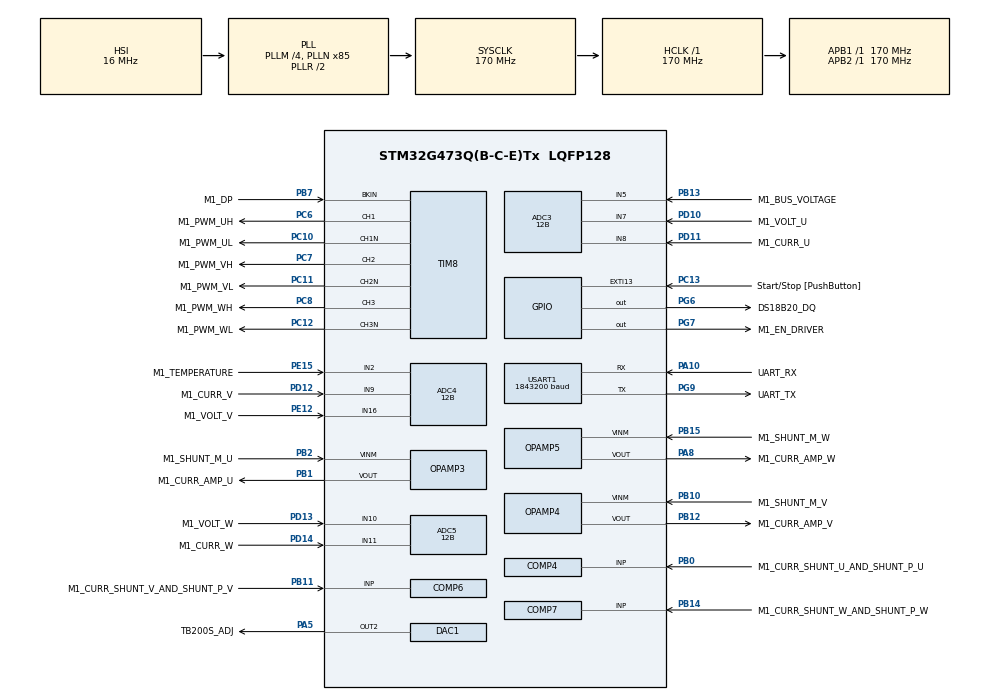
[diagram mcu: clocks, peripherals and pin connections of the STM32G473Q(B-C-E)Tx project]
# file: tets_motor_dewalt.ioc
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ADC3.Channel-1\#ChannelRegularConversion=ADC_CHANNEL_8
ADC3.Channel-2\#ChannelRegularConversion=ADC_CHANNEL_7
ADC3.Channel-3\#ChannelRegularConversion=ADC_CHANNEL_5
ADC3.ClockPrescaler=ADC_CLOCK_ASYNC_DIV1
ADC3.ContinuousConvMode=DISABLE
ADC3.DMAContinuousRequests=DISABLE
ADC3.DataAlign=ADC_DATAALIGN_LEFT
ADC3.DiscontinuousConvMode=DISABLE
ADC3.EOCSelection=ADC_EOC_SINGLE_CONV
ADC3.EnableAnalogWatchDog1=false
ADC3.EnableAnalogWatchDog2=false
ADC3.EnableAnalogWatchDog3=false
ADC3.EnableRegularConversion=ENABLE
ADC3.ExternalTrigConv=ADC_EXTERNALTRIG_T3_TRGO
ADC3.ExternalTrigConvEdge=ADC_EXTERNALTRIGCONVEDGE_FALLING
ADC3.LowPowerAutoWait=DISABLE
ADC3.NbrOfConversion=3
ADC3.NbrOfConversionFlag=1
ADC3.Offset-1\#ChannelRegularConversion=0
ADC3.Offset-2\#ChannelRegularConversion=0
ADC3.Offset-3\#ChannelRegularConversion=0
ADC3.OffsetNumber-1\#ChannelRegularConversion=ADC_OFFSET_NONE
ADC3.OffsetNumber-2\#ChannelRegularConversion=ADC_OFFSET_NONE
ADC3.OffsetNumber-3\#ChannelRegularConversion=ADC_OFFSET_NONE
ADC3.Overrun=ADC_OVR_DATA_PRESERVED
ADC3.Rank-1\#ChannelRegularConversion=1
ADC3.Rank-2\#ChannelRegularConversion=2
ADC3.Rank-3\#ChannelRegularConversion=3
ADC3.Resolution=ADC_RESOLUTION_12B
ADC3.SamplingTime-1\#ChannelRegularConversion=ADC_SAMPLETIME_6CYCLES_5
ADC3.SamplingTime-2\#ChannelRegularConversion=ADC_SAMPLETIME_6CYCLES_5
ADC3.SamplingTime-3\#ChannelRegularConversion=ADC_SAMPLETIME_6CYCLES_5
ADC3.ScanConvMode=ADC_SCAN_ENABLE
ADC3.master=1
ADC4.Channel-1\#ChannelRegularConversion=ADC_CHANNEL_9
ADC4.Channel-2\#ChannelRegularConversion=ADC_CHANNEL_16
ADC4.Channel-3\#ChannelRegularConversion=ADC_CHANNEL_2
ADC4.ClockPrescaler=ADC_CLOCK_ASYNC_DIV1
ADC4.ContinuousConvMode=DISABLE
ADC4.DMAContinuousRequests=DISABLE
ADC4.DataAlign=ADC_DATAALIGN_LEFT
ADC4.DiscontinuousConvMode=DISABLE
ADC4.EOCSelection=ADC_EOC_SINGLE_CONV
ADC4.EnableAnalogWatchDog1=false
ADC4.EnableAnalogWatchDog2=false
ADC4.EnableAnalogWatchDog3=false
ADC4.EnableRegularConversion=ENABLE
ADC4.ExternalTrigConv=ADC_EXTERNALTRIG_T3_TRGO
ADC4.ExternalTrigConvEdge=ADC_EXTERNALTRIGCONVEDGE_FALLING
ADC4.LowPowerAutoWait=DISABLE
ADC4.NbrOfConversion=3
ADC4.NbrOfConversionFlag=1
ADC4.Offset-1\#ChannelRegularConversion=0
ADC4.Offset-2\#ChannelRegularConversion=0
ADC4.Offset-3\#ChannelRegularConversion=0
ADC4.OffsetNumber-1\#ChannelRegularConversion=ADC_OFFSET_NONE
ADC4.OffsetNumber-2\#ChannelRegularConversion=ADC_OFFSET_NONE
ADC4.OffsetNumber-3\#ChannelRegularConversion=ADC_OFFSET_NONE
ADC4.Overrun=ADC_OVR_DATA_PRESERVED
ADC4.Rank-1\#ChannelRegularConversion=1
ADC4.Rank-2\#ChannelRegularConversion=2
ADC4.Rank-3\#ChannelRegularConversion=3
ADC4.Resolution=ADC_RESOLUTION_12B
ADC4.SamplingTime-1\#ChannelRegularConversion=ADC_SAMPLETIME_6CYCLES_5
ADC4.SamplingTime-2\#ChannelRegularConversion=ADC_SAMPLETIME_6CYCLES_5
ADC4.SamplingTime-3\#ChannelRegularConversion=ADC_SAMPLETIME_6CYCLES_5
ADC4.ScanConvMode=ADC_SCAN_ENABLE
ADC4.master=1
ADC5.Channel-1\#ChannelRegularConversion=ADC_CHANNEL_11
ADC5.Channel-2\#ChannelRegularConversion=ADC_CHANNEL_10
ADC5.Channel-3\#ChannelRegularConversion=ADC_CHANNEL_10
ADC5.ClockPrescaler=ADC_CLOCK_ASYNC_DIV1
ADC5.ContinuousConvMode=DISABLE
ADC5.DMAContinuousRequests=DISABLE
ADC5.DataAlign=ADC_DATAALIGN_LEFT
ADC5.DiscontinuousConvMode=DISABLE
ADC5.EOCSelection=ADC_EOC_SINGLE_CONV
ADC5.EnableAnalogWatchDog1=false
ADC5.EnableAnalogWatchDog2=false
ADC5.EnableAnalogWatchDog3=false
ADC5.EnableRegularConversion=ENABLE
ADC5.ExternalTrigConv=ADC_EXTERNALTRIG_T3_TRGO
ADC5.ExternalTrigConvEdge=ADC_EXTERNALTRIGCONVEDGE_FALLING
ADC5.LowPowerAutoWait=DISABLE
ADC5.NbrOfConversion=3
ADC5.NbrOfConversionFlag=1
ADC5.Offset-1\#ChannelRegularConversion=0
ADC5.Offset-2\#ChannelRegularConversion=0
ADC5.Offset-3\#ChannelRegularConversion=0
ADC5.OffsetNumber-1\#ChannelRegularConversion=ADC_OFFSET_NONE
ADC5.OffsetNumber-2\#ChannelRegularConversion=ADC_OFFSET_NONE
ADC5.OffsetNumber-3\#ChannelRegularConversion=ADC_OFFSET_NONE
ADC5.Overrun=ADC_OVR_DATA_PRESERVED
ADC5.Rank-1\#ChannelRegularConversion=1
ADC5.Rank-2\#ChannelRegularConversion=2
ADC5.Rank-3\#ChannelRegularConversion=3
ADC5.Resolution=ADC_RESOLUTION_12B
ADC5.SamplingTime-1\#ChannelRegularConversion=ADC_SAMPLETIME_6CYCLES_5
ADC5.SamplingTime-2\#ChannelRegularConversion=ADC_SAMPLETIME_6CYCLES_5
ADC5.SamplingTime-3\#ChannelRegularConversion=ADC_SAMPLETIME_6CYCLES_5
ADC5.ScanConvMode=ADC_SCAN_ENABLE
ADC5.master=1
DAC1.DAC_Channel-DAC_OUT2=DAC_CHANNEL_2
DAC1.DAC_ConnectOnChipPeripheral-DAC_OUT2=DAC_CHIPCONNECT_EXTERNAL
DAC1.DAC_OutputBuffer-DAC_OUT2=DAC_OUTPUTBUFFER_ENABLE
DAC3.DAC_Channel-DAC_OUT2_Int=DAC_CHANNEL_2
DAC4.DAC_Channel-DAC_OUT2_Int=DAC_CHANNEL_2
Dma.ADC3.2.Direction=DMA_PERIPH_TO_MEMORY
Dma.ADC3.2.EventEnable=DISABLE
Dma.ADC3.2.Instance=DMA2_Channel1
Dma.ADC3.2.MemDataAlignment=DMA_MDATAALIGN_HALFWORD
Dma.ADC3.2.MemInc=DMA_MINC_ENABLE
Dma.ADC3.2.Mode=DMA_CIRCULAR
Dma.ADC3.2.PeriphDataAlignment=DMA_PDATAALIGN_HALFWORD
Dma.ADC3.2.PeriphInc=DMA_PINC_DISABLE
Dma.ADC3.2.Polarity=HAL_DMAMUX_REQ_GEN_RISING
Dma.ADC3.2.Priority=DMA_PRIORITY_LOW
Dma.ADC3.2.RequestNumber=1
Dma.ADC3.2.SignalID=NONE
Dma.ADC3.2.SyncEnable=DISABLE
Dma.ADC3.2.SyncPolarity=HAL_DMAMUX_SYNC_NO_EVENT
Dma.ADC3.2.SyncRequestNumber=1
Dma.ADC3.2.SyncSignalID=NONE
Dma.ADC4.1.Direction=DMA_PERIPH_TO_MEMORY
Dma.ADC4.1.EventEnable=DISABLE
Dma.ADC4.1.Instance=DMA2_Channel2
Dma.ADC4.1.MemDataAlignment=DMA_MDATAALIGN_HALFWORD
Dma.ADC4.1.MemInc=DMA_MINC_ENABLE
Dma.ADC4.1.Mode=DMA_CIRCULAR
Dma.ADC4.1.PeriphDataAlignment=DMA_PDATAALIGN_HALFWORD
Dma.ADC4.1.PeriphInc=DMA_PINC_DISABLE
Dma.ADC4.1.Polarity=HAL_DMAMUX_REQ_GEN_RISING
Dma.ADC4.1.Priority=DMA_PRIORITY_LOW
Dma.ADC4.1.RequestNumber=1
Dma.ADC4.1.SignalID=NONE
Dma.ADC4.1.SyncEnable=DISABLE
Dma.ADC4.1.SyncPolarity=HAL_DMAMUX_SYNC_NO_EVENT
Dma.ADC4.1.SyncRequestNumber=1
Dma.ADC4.1.SyncSignalID=NONE
Dma.ADC5.0.Direction=DMA_PERIPH_TO_MEMORY
Dma.ADC5.0.EventEnable=DISABLE
Dma.ADC5.0.Instance=DMA2_Channel3
Dma.ADC5.0.MemDataAlignment=DMA_MDATAALIGN_HALFWORD
Dma.ADC5.0.MemInc=DMA_MINC_ENABLE
Dma.ADC5.0.Mode=DMA_CIRCULAR
Dma.ADC5.0.PeriphDataAlignment=DMA_PDATAALIGN_HALFWORD
Dma.ADC5.0.PeriphInc=DMA_PINC_DISABLE
Dma.ADC5.0.Polarity=HAL_DMAMUX_REQ_GEN_RISING
Dma.ADC5.0.Priority=DMA_PRIORITY_LOW
Dma.ADC5.0.RequestNumber=1
Dma.ADC5.0.SignalID=NONE
Dma.ADC5.0.SyncEnable=DISABLE
Dma.ADC5.0.SyncPolarity=HAL_DMAMUX_SYNC_NO_EVENT
Dma.ADC5.0.SyncRequestNumber=1
Dma.ADC5.0.SyncSignalID=NONE
Dma.Request0=ADC5
Dma.Request1=ADC4
Dma.Request2=ADC3
Dma.Request3=USART1_RX
Dma.Request4=USART1_TX
Dma.USART1_RX.3.Direction=DMA_PERIPH_TO_MEMORY
Dma.USART1_RX.3.EventEnable=DISABLE
Dma.USART1_RX.3.Instance=DMA1_Channel1
Dma.USART1_RX.3.MemDataAlignment=DMA_MDATAALIGN_BYTE
Dma.USART1_RX.3.MemInc=DMA_MINC_ENABLE
Dma.USART1_RX.3.Mode=DMA_NORMAL
Dma.USART1_RX.3.PeriphDataAlignment=DMA_PDATAALIGN_BYTE
Dma.USART1_RX.3.PeriphInc=DMA_PINC_DISABLE
Dma.USART1_RX.3.Polarity=HAL_DMAMUX_REQ_GEN_RISING
Dma.USART1_RX.3.Priority=DMA_PRIORITY_LOW
Dma.USART1_RX.3.RequestNumber=1
Dma.USART1_RX.3.SignalID=NONE
Dma.USART1_RX.3.SyncEnable=DISABLE
Dma.USART1_RX.3.SyncPolarity=HAL_DMAMUX_SYNC_NO_EVENT
Dma.USART1_RX.3.SyncRequestNumber=1
Dma.USART1_RX.3.SyncSignalID=NONE
Dma.USART1_TX.4.Direction=DMA_MEMORY_TO_PERIPH
Dma.USART1_TX.4.EventEnable=DISABLE
Dma.USART1_TX.4.Instance=DMA1_Channel2
Dma.USART1_TX.4.MemDataAlignment=DMA_MDATAALIGN_BYTE
Dma.USART1_TX.4.MemInc=DMA_MINC_ENABLE
Dma.USART1_TX.4.Mode=DMA_NORMAL
Dma.USART1_TX.4.PeriphDataAlignment=DMA_PDATAALIGN_BYTE
Dma.USART1_TX.4.PeriphInc=DMA_PINC_DISABLE
Dma.USART1_TX.4.Polarity=HAL_DMAMUX_REQ_GEN_RISING
Dma.USART1_TX.4.Priority=DMA_PRIORITY_LOW
Dma.USART1_TX.4.RequestNumber=1
Dma.USART1_TX.4.SignalID=NONE
Dma.USART1_TX.4.SyncEnable=DISABLE
Dma.USART1_TX.4.SyncPolarity=HAL_DMAMUX_SYNC_NO_EVENT
Dma.USART1_TX.4.SyncRequestNumber=1
Dma.USART1_TX.4.SyncSignalID=NONE
ExtraMW=MotorControl
ExtraMW.MotorControl.Config=MotorControl
ExtraMW.MotorControl.Mode=MotorControl
ExtraMW.MotorControl.Root=MCSDK_v6.4.2-Full/MotorControl
ExtraMW.MotorControl.Template=templates
Mcu.Family=STM32G4
Mcu.Name=STM32G473Q(B-C-E)Tx
Mcu.Package=LQFP128
MotorControl.ADC_CLOCK_WB_DIV=1
MotorControl.ADC_EXTRA_REG_CON_FAKE={'ADC3'\:[],'ADC4'\:[],'ADC5'\:[{'ip'\:'ADC5','channel'\:'ADC_Channel_10','pin'\:'PD13','isChShared'\:false,'sampling_time'\:6,'sampling_cycles'\:5,'label'\:'Fake','motor'\:1,'type'\:'Fake','rank'\:2}]}
MotorControl.ADC_MODE_REG_CON={'ADC3'\:true,'ADC4'\:true,'ADC5'\:true}
MotorControl.ADC_REFERENCE_VOLTAGE=3.3
MotorControl.ADC_REGULAR_REQS=[{'ip'\:'ADC3','channel'\:'ADC_Channel_8','pin'\:'PD11','isChShared'\:false,'sampling_time'\:6,'sampling_cycles'\:5,'label'\:'CURR_U','motor'\:1,'type'\:'CURR_U','rank'\:1},{'ip'\:'ADC3','channel'\:'ADC_Channel_7','pin'\:'PD10','isChShared'\:false,'sampling_time'\:6,'sampling_cycles'\:5,'label'\:'VOLT_U','motor'\:1,'type'\:'VOLT_U','rank'\:2},{'ip'\:'ADC3','channel'\:'ADC_Channel_5','pin'\:'PB13','isChShared'\:false,'sampling_time'\:6,'sampling_cycles'\:5,'label'\:'BUS_VOLTAGE','motor'\:1,'type'\:'BUS_VOLTAGE','rank'\:3},{'ip'\:'ADC4','channel'\:'ADC_Channel_9','pin'\:'PD12','isChShared'\:false,'sampling_time'\:6,'sampling_cycles'\:5,'label'\:'CURR_V','motor'\:1,'type'\:'CURR_V','rank'\:1},{'ip'\:'ADC4','channel'\:'ADC_Channel_16','pin'\:'PE12','isChShared'\:false,'sampling_time'\:6,'sampling_cycles'\:5,'label'\:'VOLT_V','motor'\:1,'type'\:'VOLT_V','rank'\:2},{'ip'\:'ADC4','channel'\:'ADC_Channel_2','pin'\:'PE15','isChShared'\:false,'sampling_time'\:6,'sampling_cycles'\:5,'label'\:'TEMPERATURE','motor'\:1,'type'\:'TEMPERATURE','rank'\:3},{'ip'\:'ADC5','channel'\:'ADC_Channel_11','pin'\:'PD14','isChShared'\:false,'sampling_time'\:6,'sampling_cycles'\:5,'label'\:'CURR_W','motor'\:1,'type'\:'CURR_W','rank'\:1},{'ip'\:'ADC5','channel'\:'ADC_Channel_10','pin'\:'PD13','isChShared'\:false,'sampling_time'\:6,'sampling_cycles'\:5,'label'\:'VOLT_W','motor'\:1,'type'\:'VOLT_W','rank'\:2}]
MotorControl.BOARD=B-G473E-ZEST1S
MotorControl.BUS_VOLTAGE_READING=true
MotorControl.CCMRAM_ENABLED=false
MotorControl.CLOCK_FREQUENCY=CPU_CLK_170_MHZ
MotorControl.CLOCK_SOURCE=INTERNAL
MotorControl.CPU_CLK_170_MHZ=true
MotorControl.CTLBOARD_NAME=B-G473E-ZEST1S
MotorControl.CUBE_MX_VER=6.17.0
MotorControl.CURRENT_READING_TOPOLOGY=THREE_SHUNT_INDEPENDENT_RESOURCES
MotorControl.CURR_SAMPLING_TIME=6
MotorControl.DBG_MCU_LOAD_MEASURE=false
MotorControl.DEBUG_DAC_FUNCTIONALITY_EN=false
MotorControl.DP_EMERGENCY_STOP_GPIO_PIN=LL_GPIO_PIN_7
MotorControl.DP_EMERGENCY_STOP_GPIO_PORT=GPIOB
MotorControl.DRIVES_NUMBER_SELECTION=SINGLEDRIVE
MotorControl.DRIVE_NUMBER=1
MotorControl.DRIVE_TYPE=FOC
MotorControl.ENCODER_AVAILABLE=false
MotorControl.ENCODER_PPR=400
MotorControl.EN_DRIVER_AVAILABLE=true
MotorControl.EN_DRIVER_GPIO_PIN=LL_GPIO_PIN_7
MotorControl.EN_DRIVER_GPIO_PORT=GPIOG
MotorControl.EN_DRIVER_POLARITY=ACTIVE_HIGH
MotorControl.EXT_CLOCK_FREQUENCY=INT_RC_OSC
MotorControl.FEEDBACK_NET_FILTERING=false
MotorControl.FLASH_SIZE=512
MotorControl.HALL_SENSORS_AVAILABLE=false
MotorControl.HIGH_SIDE_IDLE_STATE=false
MotorControl.HWV_CS=ThreeShunt_RawCurrents_Differential_ExternalGain_FilteredADCInput
MotorControl.HWV_DP=SingleErrorTrigger_FixedReference
MotorControl.HWV_OCP=ThreeShunt_RawCurrents_Protection_IntRef
MotorControl.HWV_PWM=DrivingHighAndLowSidesAndMasterEnable
MotorControl.HW_COMPLEMENTED_LOW_SIDE=false
MotorControl.HW_DEAD_TIME_NS=250
MotorControl.INT_RC_OSC=true
MotorControl.IPs=CORDIC,NVIC,RCC,SYS,MotorControl,TIM8,COMP4,DAC3,COMP6,DAC4,COMP7,OPAMP3,OPAMP4,OPAMP5,TIM3,ADC3,ADC4,ADC5,USART1,DMA
MotorControl.LOW_MEMORY_FOOTPRINT_REG=false
MotorControl.LOW_SIDE_IDLE_STATE=false
MotorControl.LOW_SIDE_SIGNALS_ENABLING=LS_PWM_TIMER
MotorControl.M1_AMPLIFICATION_GAIN=15
MotorControl.M1_ANGC={0,0,0,0,0,0,0,0}
MotorControl.M1_ANGLE_COMPENSATION_FACTOR=1.98
MotorControl.M1_AUXILIARY_SPEED_SENSOR=NONE
MotorControl.M1_BOARD_LIMIT_ACCEL_HIGH=10
MotorControl.M1_BOARD_LIMIT_ACCEL_LOW=7.5
MotorControl.M1_BOARD_LIMIT_REGEN_HIGH=19.44
MotorControl.M1_BOARD_LIMIT_REGEN_LOW=17.28
MotorControl.M1_BOARD_MAX_CURRENT=30
MotorControl.M1_BOARD_SOFT_OVERCURRENT_TRIP=30
MotorControl.M1_BUS_PROTECTION=false
MotorControl.M1_BUS_VOLTAGE_READING=true
MotorControl.M1_CONSTANT1_D=27069
MotorControl.M1_CONSTANT1_Q=27069
MotorControl.M1_CONSTANT2_QD=3745
MotorControl.M1_CS_ADC_NUM=3
MotorControl.M1_CS_ADC_PHASE_SHARED=NONE
MotorControl.M1_CS_ADC_RANK_U=1
MotorControl.M1_CS_ADC_RANK_V=1
MotorControl.M1_CS_ADC_RANK_W=1
MotorControl.M1_CS_ADC_U=ADC3
MotorControl.M1_CS_ADC_V=ADC4
MotorControl.M1_CS_ADC_W=ADC5
MotorControl.M1_CS_CHANNEL_U=8
MotorControl.M1_CS_CHANNEL_V=9
MotorControl.M1_CS_CHANNEL_W=11
MotorControl.M1_CS_OPAMP_DYNAMIC_OUTPUT_SWITCH=false
MotorControl.M1_CS_OPAMP_NUM=3
MotorControl.M1_CS_OPAMP_PHASE_SHARED=NONE
MotorControl.M1_CS_OPAMP_U=OPAMP3
MotorControl.M1_CS_OPAMP_V=OPAMP4
MotorControl.M1_CS_OPAMP_W=OPAMP5
MotorControl.M1_CURRENT_AMPLIFICATION_TOPO=INT_DIFFERENTIAL
MotorControl.M1_CURRENT_SCALE=440
MotorControl.M1_CURRENT_SENSING_TOPO=THREE_SHUNT
MotorControl.M1_CURR_SAMPLING_TIME=6
MotorControl.M1_DAC_CURRENT_THRESHOLD=4369
MotorControl.M1_DBG_OPEN_LOOP_ENABLE=false
MotorControl.M1_DC_CURRENT_RS_MEAS=5
MotorControl.M1_DEFAULT_CONTROL_MODE=STC_SPEED_MODE
MotorControl.M1_DEFAULT_FLUX_COMPONENT=0
MotorControl.M1_DEFAULT_TARGET_SPEED_RPM=1440
MotorControl.M1_DEFAULT_TORQUE_COMPONENT=0
MotorControl.M1_DISCONTINUOUS_PWM=false
MotorControl.M1_DP_BKIN_FILTER=4
MotorControl.M1_DP_BKIN_MODE=EXT_MODE
MotorControl.M1_DP_BKIN_POLARITY=EMSTOP_ACTIVE_LOW
MotorControl.M1_DP_DESTINATION=TIM_BKIN
MotorControl.M1_DP_TOPOLOGY=EXTERNAL
MotorControl.M1_DRIVE_TYPE=FOC
MotorControl.M1_ENCODER_PPR=400
MotorControl.M1_FREQUENCY_SCALE=267
MotorControl.M1_HALL_PHASE_SHIFT=300
MotorControl.M1_HALL_SENSORS_PLACEMENT=DEGREES_120
MotorControl.M1_HIGH_SIDE_IDLE_STATE=false
MotorControl.M1_HSO_ADC_SAMPLING_TIME=6.5
MotorControl.M1_HSO_DMACH_ADC_U=1
MotorControl.M1_HSO_DMACH_ADC_V=2
MotorControl.M1_HSO_DMACH_ADC_W=3
MotorControl.M1_HSO_DMA_ADC_U=DMA2
MotorControl.M1_HSO_DMA_ADC_V=DMA2
MotorControl.M1_HSO_DMA_ADC_W=DMA2
MotorControl.M1_HSO_EXTRA_TIM_SELEC=TIM3
MotorControl.M1_HSO_IRQ_HANDLER_DMA_ADC_U=DMA2_Channel1_IRQHandler
MotorControl.M1_HSO_IRQ_HANDLER_DMA_ADC_V=DMA2_Channel2_IRQHandler
MotorControl.M1_HSO_IRQ_HANDLER_DMA_ADC_W=DMA2_Channel3_IRQHandler
MotorControl.M1_HW_DEAD_TIME_NS=250
MotorControl.M1_ICL_ENABLED=false
MotorControl.M1_ID_DEMAG=-5
MotorControl.M1_INT_AMP_OPAMP3_PIN=[{'mode'\:'Standalone','name'\:'PB0','signal'\:'OPAMP3_VINP','label'\:'SHUNT_P_U'},{'mode'\:'Standalone','name'\:'PB2','signal'\:'OPAMP3_VINM','label'\:'SHUNT_M_U'},{'mode'\:'Standalone','name'\:'PB1','signal'\:'OPAMP3_VOUT','label'\:'CURR_AMP_U'}]
MotorControl.M1_INT_AMP_OPAMP4_PIN=[{'mode'\:'Standalone','name'\:'PB11','signal'\:'OPAMP4_VINP','label'\:'SHUNT_P_V'},{'mode'\:'Standalone','name'\:'PB10','signal'\:'OPAMP4_VINM','label'\:'SHUNT_M_V'},{'mode'\:'Standalone','name'\:'PB12','signal'\:'OPAMP4_VOUT','label'\:'CURR_AMP_V'}]
MotorControl.M1_INT_AMP_OPAMP5_PIN=[{'mode'\:'Standalone','name'\:'PB14','signal'\:'OPAMP5_VINP','label'\:'SHUNT_P_W'},{'mode'\:'Standalone','name'\:'PB15','signal'\:'OPAMP5_VINM','label'\:'SHUNT_M_W'},{'mode'\:'Standalone','name'\:'PA8','signal'\:'OPAMP5_VOUT','label'\:'CURR_AMP_W'}]
MotorControl.M1_INT_AMP_OPAMPS=['OPAMP3','OPAMP4','OPAMP5']
MotorControl.M1_IQMAX=28
MotorControl.M1_KSAMPLE_DELAY=0.2
MotorControl.M1_LDLQ_RATIO=1.000
MotorControl.M1_LOW_SIDE_IDLE_STATE=false
MotorControl.M1_LOW_SIDE_SIGNALS_ENABLING=LS_PWM_TIMER
MotorControl.M1_LS=0.000017
MotorControl.M1_MAX_APPLICATION_SPEED=4500
MotorControl.M1_MAX_MODULATION_INDEX=100
MotorControl.M1_MIN_APPLICATION_SPEED=0
MotorControl.M1_MOTOR_MAX_SPEED_RPM=4500
MotorControl.M1_MOTOR_NAME=DeWalt DCD996NT-TY2 Brus
MotorControl.M1_MOTOR_RATED_FLUX=0.013006791
MotorControl.M1_MOTOR_VOLTAGE_CONSTANT=0.5
MotorControl.M1_NOMINAL_BUS_VOLTAGE_V=18
MotorControl.M1_NOMINAL_CURRENT=30
MotorControl.M1_OCP_BKIN_FILTER=4
MotorControl.M1_OCP_BKIN_MODE=INT_MODE
MotorControl.M1_OCP_BKIN_POLARITY=EMSTOP_ACTIVE_HIGH
MotorControl.M1_OCP_COMP_SRC=DAC
MotorControl.M1_OCP_COMP_U=COMP4
MotorControl.M1_OCP_COMP_V=COMP6
MotorControl.M1_OCP_COMP_W=COMP7
MotorControl.M1_OCP_DAC_CHANNEL_U=OUT2
MotorControl.M1_OCP_DAC_CHANNEL_V=OUT2
MotorControl.M1_OCP_DAC_CHANNEL_W=OUT1
MotorControl.M1_OCP_DAC_U=DAC3
MotorControl.M1_OCP_DAC_V=DAC4
MotorControl.M1_OCP_DAC_W=DAC4
MotorControl.M1_OCP_DESTINATION=TIM_BKIN
MotorControl.M1_OCP_TOPOLOGY=EMBEDDED
MotorControl.M1_OFST={0,0,0,0,0,0,0,0}
MotorControl.M1_ON_OVER_VOLTAGE=TURN_OFF_PWM
MotorControl.M1_OVERMODULATION=false
MotorControl.M1_OVP_THRESHOLD_HIGH=21.6
MotorControl.M1_OV_TEMPERATURE_HYSTERESIS_C=10
MotorControl.M1_OV_TEMPERATURE_PROT_ENABLING=true
MotorControl.M1_OV_TEMPERATURE_THRESHOLD_C=120
MotorControl.M1_OV_VOLTAGE_PROT_ENABLING=true
MotorControl.M1_OV_VOLTAGE_THRESHOLD_V=21.6
MotorControl.M1_PHASE_VOLTAGE_PARTITIONING_FACTOR=0.063
MotorControl.M1_PID_FLUX_KD_DEFAULT=100
MotorControl.M1_PID_FLUX_KI_DEFAULT=751
MotorControl.M1_PID_FLUX_KP_DEFAULT=2553
MotorControl.M1_PID_SPD_KI=7.15693773016927
MotorControl.M1_PID_SPD_KP=0.29673580049046194
MotorControl.M1_PID_TORQUE_KD_DEFAULT=100
MotorControl.M1_PID_TORQUE_KI_DEFAULT=751
MotorControl.M1_PID_TORQUE_KP_DEFAULT=2553
MotorControl.M1_POLE_PAIR_NUM=2
MotorControl.M1_POLPULSES_ACTIVATTION_FLAG=true
MotorControl.M1_POLPULSES_NB_DECAY_PERIODS=2
MotorControl.M1_POLPULSES_NB_PULSE_PERIODS=2
MotorControl.M1_POLPULSES_PULSE_CURRENT_GOAL=14.0
MotorControl.M1_POTENTIOMETER_ENABLE=false
MotorControl.M1_POWERBOARD_NAME=STDES-LVHP01_48V
MotorControl.M1_PWM_CHARGE_BOOT_CAP_DUTY_CYCLES=0.000
MotorControl.M1_PWM_CHARGE_BOOT_CAP_MS=10
MotorControl.M1_PWM_DRIVER_PN=L6491
MotorControl.M1_PWM_FREQUENCY=16000
MotorControl.M1_PWM_TIMER_BRK_IRQ=TIM8_BRK
MotorControl.M1_PWM_TIMER_CC_IRQ=TIM8_CC
MotorControl.M1_PWM_TIMER_SELECTION=PWM_TIM8
MotorControl.M1_PWM_TIMER_UP_IRQ=TIM8_UP
MotorControl.M1_REGULATION_EXECUTION_RATE=1
MotorControl.M1_RS=0.01
MotorControl.M1_RSDC_ESTIMATION_FLAG=true
MotorControl.M1_RSHUNT=0.001
MotorControl.M1_SEGDIV=0
MotorControl.M1_SHARED_SIGNAL_ENABLE=false
MotorControl.M1_SPD_DIFFERENTIAL_TERM_ENABLING=false
MotorControl.M1_SPEED_LOOP_FREQUENCY_HZ=1000
MotorControl.M1_SPEED_SENSOR=HSO
MotorControl.M1_SS_MEAS_ERRORS_BEFORE_FAULTS=3
MotorControl.M1_SW_DEADTIME_NS=225
MotorControl.M1_T0_C=25
MotorControl.M1_TEMPERATURE_READING=true
MotorControl.M1_TEMP_ADC_RANK=3
MotorControl.M1_TEMP_ADC_SAMPLING_TIME=6
MotorControl.M1_TEMP_FDBK_ADC=ADC4
MotorControl.M1_TEMP_FDBK_CHANNEL=ADC_CHANNEL_2
MotorControl.M1_TNOISE_NS=500
MotorControl.M1_TRISE_NS=100
MotorControl.M1_T_MAX=120
MotorControl.M1_UD_VOLTAGE_THRESHOLD_V=5.0
MotorControl.M1_USE_INTERNAL_OPAMP=true
MotorControl.M1_UV_VOLTAGE_PROT_ENABLING=true
MotorControl.M1_V0_V=0.29
MotorControl.M1_VBUS_ADC=ADC3
MotorControl.M1_VBUS_ADC_RANK=3
MotorControl.M1_VBUS_ADC_SAMPLING_TIME=6
MotorControl.M1_VBUS_CHANNEL=ADC_CHANNEL_5
MotorControl.M1_VBUS_PARTITIONING_FACTOR=0.02900232018561485
MotorControl.M1_VOLTAGE_FILTER_POLE_RPS=3154
MotorControl.M1_VOLTAGE_SCALE=105
MotorControl.M1_VS_ADC_RANK_U=2
MotorControl.M1_VS_ADC_RANK_V=2
MotorControl.M1_VS_ADC_RANK_W=2
MotorControl.M1_VS_ADC_U=ADC3
MotorControl.M1_VS_ADC_V=ADC4
MotorControl.M1_VS_ADC_W=ADC5
MotorControl.M1_dV_dT=0.025
MotorControl.MAX_READABLE_CURRENT=110
MotorControl.MCPA_OVER_UART_A_STREAM=10
MotorControl.MCP_ASPEP_OVER_UART=true
MotorControl.MCP_ASYNC_EN=true
MotorControl.MCP_ASYNC_OVER_ASPEP_EN=true
MotorControl.MCP_ASYNC_OVER_UART_A_EN=true
MotorControl.MCP_DMACH_RX_UART_A=1
MotorControl.MCP_DMACH_TX_UART_A=2
MotorControl.MCP_DMA_RX_UART_A=DMA1
MotorControl.MCP_DMA_TX_UART_A=DMA1
MotorControl.MCP_EN=true
MotorControl.MCP_IRQ_HANDLER_DMA_RX_UART_A=DMA1_Channel1_IRQHandler
MotorControl.MCP_IRQ_HANDLER_UART_A=USART1_IRQHandler
MotorControl.MCP_OVER_ASPEP_EN=true
MotorControl.MCP_OVER_STLNK_EN=false
MotorControl.MCP_OVER_UART_A_EN=true
MotorControl.MCP_OVER_UART_B_EN=false
MotorControl.MCP_RX_SYNC_PAYLOAD_MAX=256
MotorControl.MCP_TX_ASYNC_PAYLOAD_MAX_UART_A=2048
MotorControl.MCP_TX_SYNC_PAYLOAD_MAX=256
MotorControl.MCU=STM32G473QE
MotorControl.MCU_FAMILY=STM32G4
MotorControl.MCU_LINE=STM32G4x3
MotorControl.MCU_NAME=STM32G473Q(B-C-E)Tx
MotorControl.MCU_PACKAGE=LQFP128
MotorControl.MCU_TYPE=STM32G473QE
MotorControl.MCU_USERNAME=STM32G473QETx
MotorControl.MC_WORKBENCH_VERSION=6.4.2
MotorControl.MOTOR_PROFILER=false
MotorControl.MOTOR_TYPE=PMSM
MotorControl.OCPA_DAC_INTERNAL_PIN=true
MotorControl.OCPA_INVERTINGINPUT=COMPX_InvertingInput_DAC3
MotorControl.OCPA_INVERTINGINPUT_DAC_OUT=OUT2
MotorControl.OCPA_INVERTINGINPUT_GPIO_PIN=LL_GPIO_PIN_4
MotorControl.OCPA_INVERTINGINPUT_GPIO_PORT=GPIOA
MotorControl.OCPA_INVERTINGINPUT_MODE=INT_MODE
MotorControl.OCPA_NONINVERTINGINPUT=COMP4_NonInvertingInput_PB0
MotorControl.OCPA_NONINVERTINGINPUT_GPIO_PIN=LL_GPIO_PIN_0
MotorControl.OCPA_NONINVERTINGINPUT_GPIO_PORT=GPIOB
MotorControl.OCPA_OUTPUT=COMP_Output_TIM1BKIN2
MotorControl.OCPA_OUTPUTPOL=COMP_OutputPol_NonInverted
MotorControl.OCPA_OUTPUT_GPIO_PIN=LL_GPIO_PIN_4
MotorControl.OCPA_OUTPUT_GPIO_PORT=GPIOA
MotorControl.OCPA_OUTPUT_MODE=INT_MODE
MotorControl.OCPA_SELECTION=COMP4
MotorControl.OCPB_DAC_INTERNAL_PIN=true
MotorControl.OCPB_INVERTINGINPUT=COMPX_InvertingInput_DAC4
MotorControl.OCPB_INVERTINGINPUT_DAC_OUT=OUT2
MotorControl.OCPB_INVERTINGINPUT_GPIO_PIN=LL_GPIO_PIN_4
MotorControl.OCPB_INVERTINGINPUT_GPIO_PORT=GPIOA
MotorControl.OCPB_INVERTINGINPUT_MODE=INT_MODE
MotorControl.OCPB_NONINVERTINGINPUT=COMP6_NonInvertingInput_PB11
MotorControl.OCPB_NONINVERTINGINPUT_GPIO_PIN=LL_GPIO_PIN_11
MotorControl.OCPB_NONINVERTINGINPUT_GPIO_PORT=GPIOB
MotorControl.OCPB_OUTPUT=COMP_Output_TIM1BKIN2
MotorControl.OCPB_OUTPUTPOL=COMP_OutputPol_NonInverted
MotorControl.OCPB_OUTPUT_GPIO_PIN=LL_GPIO_PIN_4
MotorControl.OCPB_OUTPUT_GPIO_PORT=GPIOA
MotorControl.OCPB_OUTPUT_MODE=INT_MODE
MotorControl.OCPB_SELECTION=COMP6
MotorControl.OCPC_DAC_INTERNAL_PIN=true
MotorControl.OCPC_INVERTINGINPUT=COMPX_InvertingInput_DAC4
MotorControl.OCPC_INVERTINGINPUT_DAC_OUT=OUT1
MotorControl.OCPC_INVERTINGINPUT_GPIO_PIN=LL_GPIO_PIN_4
MotorControl.OCPC_INVERTINGINPUT_GPIO_PORT=GPIOA
MotorControl.OCPC_INVERTINGINPUT_MODE=INT_MODE
MotorControl.OCPC_NONINVERTINGINPUT=COMP7_NonInvertingInput_PB14
MotorControl.OCPC_NONINVERTINGINPUT_GPIO_PIN=LL_GPIO_PIN_14
MotorControl.OCPC_NONINVERTINGINPUT_GPIO_PORT=GPIOB
MotorControl.OCPC_OUTPUT=COMP_Output_TIM1BKIN2
MotorControl.OCPC_OUTPUTPOL=COMP_OutputPol_NonInverted
MotorControl.OCPC_OUTPUT_GPIO_PIN=LL_GPIO_PIN_4
MotorControl.OCPC_OUTPUT_GPIO_PORT=GPIOA
MotorControl.OCPC_OUTPUT_MODE=INT_MODE
MotorControl.OCPC_SELECTION=COMP7
MotorControl.OCP_FILTER=COMP_Mode_HighSpeed
MotorControl.OCP_INVERTINGINPUT=COMPX_InvertingInput_V_REF
MotorControl.OCP_INVERTINGINPUT_MODE=INT_MODE
MotorControl.OCP_SELECTION=COMP1
MotorControl.ON_OVER_VOLTAGE=TURN_OFF_PWM
MotorControl.OPAMP_PGAGAIN=OPAMP_OPAMP_PGAGain_16
MotorControl.OPAMP_TYPE_GAIN=EXTERNAL
MotorControl.OV_TEMPERATURE_PROT_ENABLING=true
MotorControl.OV_VOLTAGE_PROT_ENABLING=true
MotorControl.PHASE_UH_GPIO_PIN=LL_GPIO_PIN_6
MotorControl.PHASE_UH_GPIO_PORT=GPIOC
MotorControl.PHASE_UH_POLARITY=H_ACTIVE_HIGH
MotorControl.PHASE_UL_GPIO_PIN=LL_GPIO_PIN_10
MotorControl.PHASE_UL_GPIO_PORT=GPIOC
MotorControl.PHASE_UL_POLARITY=L_ACTIVE_LOW
MotorControl.PHASE_U_PWM_CHANNEL=TIM_Channel_1
MotorControl.PHASE_VH_GPIO_PIN=LL_GPIO_PIN_7
MotorControl.PHASE_VH_GPIO_PORT=GPIOC
MotorControl.PHASE_VH_POLARITY=H_ACTIVE_HIGH
MotorControl.PHASE_VL_GPIO_PIN=LL_GPIO_PIN_11
MotorControl.PHASE_VL_GPIO_PORT=GPIOC
MotorControl.PHASE_VL_POLARITY=L_ACTIVE_LOW
MotorControl.PHASE_V_PWM_CHANNEL=TIM_Channel_2
MotorControl.PHASE_WH_GPIO_PIN=LL_GPIO_PIN_8
MotorControl.PHASE_WH_GPIO_PORT=GPIOC
MotorControl.PHASE_WH_POLARITY=H_ACTIVE_HIGH
MotorControl.PHASE_WL_GPIO_PIN=LL_GPIO_PIN_12
MotorControl.PHASE_WL_GPIO_PORT=GPIOC
MotorControl.PHASE_WL_POLARITY=L_ACTIVE_LOW
MotorControl.PHASE_W_PWM_CHANNEL=TIM_Channel_3
MotorControl.POTENTIOMETER_READING=false
MotorControl.PWM_FREQUENCY=16000
MotorControl.PWM_TIMER_SELECTION=PWM_TIM8
MotorControl.REGULATION_EXECUTION_RATE=1
MotorControl.RTOS=NONE
MotorControl.R_BRAKE_SWITCH_OFF_THRES_V=17
MotorControl.SENSORLESS_HIGHSPEEDOBSERVER=true
MotorControl.SINGLEDRIVE=true
MotorControl.SPD_DIFFERENTIAL_TERM_ENABLING=false
MotorControl.SPEED_SENSOR_SELECTION=SENSORLESS_HIGHSPEEDOBSERVER
MotorControl.START_STOP_BTN=true
MotorControl.START_STOP_GPIO_IRQ=EXTI15_10
MotorControl.START_STOP_GPIO_PIN=LL_GPIO_PIN_13
MotorControl.START_STOP_GPIO_PORT=GPIOC
MotorControl.START_STOP_POLARITY=DIN_ACTIVE_LOW
MotorControl.START_STOP_POLARITY_EDGE=GPIO_PULLUP
MotorControl.STM32G473QE=true
MotorControl.SW_DEADTIME_NS=225
MotorControl.TEMPERATURE_READING=true
MotorControl.TEMP_ADC_SAMPLING_TIME=6
MotorControl.TEMP_FDBK_ADC=ADC4
MotorControl.TEMP_FDBK_CHANNEL=ADC_CHANNEL_2
MotorControl.TEMP_FDBK_GPIO_PIN=LL_GPIO_PIN_15
MotorControl.TEMP_FDBK_GPIO_PORT=GPIOE
MotorControl.TFDIFFERENTIAL_TERM_ENABLING=false
MotorControl.THREE_SHUNT_INDEPENDENT_RESOURCES=true
MotorControl.TRISE_NS=100
MotorControl.USART_RX_GPIO_PIN=LL_GPIO_PIN_10
MotorControl.USART_RX_GPIO_PORT=GPIOA
MotorControl.USART_SELECTION=USE_USART1
MotorControl.USART_SELECTION_A=USART1
MotorControl.USART_SPEED=1843200
MotorControl.USART_TX_GPIO_PIN=LL_GPIO_PIN_9
MotorControl.USART_TX_GPIO_PORT=GPIOG
MotorControl.USE_INTERNAL_OPAMP=true
MotorControl.UV_VOLTAGE_PROT_ENABLING=true
MotorControl.VBUS_ADC=ADC3
MotorControl.VBUS_ADC_SAMPLING_TIME=6
MotorControl.VBUS_CHANNEL=ADC_CHANNEL_5
MotorControl.VBUS_GPIO_PIN=LL_GPIO_PIN_13
MotorControl.VBUS_GPIO_PORT=GPIOB
MotorControl.WB_MX_HEAPSIZE=0x200
MotorControl.WB_MX_STACKSIZE=0x400
MotorControl.WB_MX_TRUSTZONE_AVAILABLE=false
MotorControl.WB_UI_CUTOFF_FREQUENCY=6000
MotorControl.WB_UI_DP_DISABLING_ENABLE=false
MotorControl.WB_UI_ENCODER_HAS_INDEX_PIN=false
MotorControl.WB_UI_FLUX_TARGET=0
MotorControl.WB_UI_FRICTION=14
MotorControl.WB_UI_GON=1
MotorControl.WB_UI_GOP=15
MotorControl.WB_UI_INERTIA=5
MotorControl.WB_UI_MAGNETIC_STRUCTURE=SM-PMSM
MotorControl.WB_UI_MAX_CURRENT=30
MotorControl.WB_UI_MAX_NOMINAL_DC_VOLTAGE=18
MotorControl.WB_UI_MAX_PWMFREQUENCY=80000
MotorControl.WB_UI_MOTOR_DESCRIPTION=Estimated DeWalt DCD996NT-TY2 18V XR brushless drill motor profile with a 30 A global software current ceiling. The autonomous B2 profile uses 25 A Iq and 28 A total. Public sources provide tool/gearbox specs, not internal PMSM electrical parameters; verify Rs, Ls, Ke/BEMF and pole pairs experimentally before nominal operation.
MotorControl.WB_UI_OCP_THRESHOLD=110
MotorControl.WB_UI_PW_BOARD_MAX_RATED_CURRENT=110
MotorControl.WB_UI_PW_BOARD_MAX_VOLTAGE=48
MotorControl.WB_UI_PW_BOARD_MIN_VOLTAGE=5
MotorControl.WB_UI_VPOL=1.65
MotorControl.WB_UI_VPOL_K=0.11
MotorControl.WB_to_Mx_template_version=25-05-06
MotorControl.WB_to_Mx_version=6.4.2
NVIC.DMA1_Channel1_IRQn=true\:3\:0\:true\:true\:false\:5\:true\:true\:true
NVIC.DMA2_Channel1_IRQn=true\:1\:0\:true\:true\:false\:4\:true\:true\:true
NVIC.DMA2_Channel2_IRQn=true\:1\:0\:true\:true\:false\:3\:true\:true\:true
NVIC.DMA2_Channel3_IRQn=true\:1\:0\:true\:true\:false\:2\:true\:true\:true
NVIC.EXTI15_10_IRQn=true\:3\:0\:false\:true\:false\:9\:true\:true\:true
NVIC.PriorityGroup=NVIC_PRIORITYGROUP_3
NVIC.TIM8_BRK_IRQn=true\:4\:1\:true\:true\:false\:6\:true\:true\:true
NVIC.TIM8_CC_IRQn=true\:0\:0\:true\:true\:false\:8\:true\:true\:true
NVIC.TIM8_UP_IRQn=true\:0\:0\:false\:true\:false\:7\:true\:true\:true
NVIC.USART1_IRQn=true\:3\:1\:true\:true\:false\:1\:true\:true\:true
PA10.GPIO_Label=UART_RX
PA10.GPIO_Mode=GPIO_MODE_AF_PP
PA10.GPIO_PuPd=GPIO_NOPULL
PA10.GPIO_Speed=GPIO_SPEED_FREQ_LOW
PA10.Mode=Asynchronous
PA10.Signal=USART1_RX
PA5.GPIO_Label=TB200S_ADJ
PA5.Mode=OUT2
PA5.Signal=DAC1_OUT2
PA8.GPIO_Label=M1_CURR_AMP_W
PA8.Mode=Standalone
PA8.Signal=OPAMP5_VOUT
PB0.GPIO_Label=M1_CURR_SHUNT_U_AND_SHUNT_P_U
PB0.Signal=SharedAnalog_PB0
PB1.GPIO_Label=M1_CURR_AMP_U
PB1.Mode=Standalone
PB1.Signal=OPAMP3_VOUT
PB10.GPIO_Label=M1_SHUNT_M_V
PB10.Mode=Standalone
PB10.Signal=OPAMP4_VINM
PB11.GPIO_Label=M1_CURR_SHUNT_V_AND_SHUNT_P_V
PB11.Signal=SharedAnalog_PB11
PB12.GPIO_Label=M1_CURR_AMP_V
PB12.Mode=Standalone
PB12.Signal=OPAMP4_VOUT
PB13.GPIO_Label=M1_BUS_VOLTAGE
PB13.Mode=IN5-Single-Ended
PB13.Signal=ADC3_IN5
PB14.GPIO_Label=M1_CURR_SHUNT_W_AND_SHUNT_P_W
PB14.Signal=SharedAnalog_PB14
PB15.GPIO_Label=M1_SHUNT_M_W
PB15.Mode=Standalone
PB15.Signal=OPAMP5_VINM
PB2.GPIO_Label=M1_SHUNT_M_U
PB2.Mode=Standalone
PB2.Signal=OPAMP3_VINM
PB7.GPIO_Label=M1_DP
PB7.GPIO_PuPd=GPIO_PULLUP
PB7.Mode=Activate-Break-Input
PB7.Signal=TIM8_BKIN
PC10.GPIO_Label=M1_PWM_UL
PC10.GPIO_PuPd=GPIO_PULLUP
PC10.GPIO_Speed=GPIO_SPEED_FREQ_HIGH
PC10.Mode=PWM Generation1 CH1 CH1N
PC10.Signal=TIM8_CH1N
PC11.GPIO_Label=M1_PWM_VL
PC11.GPIO_PuPd=GPIO_PULLUP
PC11.GPIO_Speed=GPIO_SPEED_FREQ_HIGH
PC11.Mode=PWM Generation2 CH2 CH2N
PC11.Signal=TIM8_CH2N
PC12.GPIO_Label=M1_PWM_WL
PC12.GPIO_PuPd=GPIO_PULLUP
PC12.GPIO_Speed=GPIO_SPEED_FREQ_HIGH
PC12.Mode=PWM Generation3 CH3 CH3N
PC12.Signal=TIM8_CH3N
PC13.GPIO_Label=Start/Stop [PushButton]
PC13.GPIO_ModeDefaultEXTI=GPIO_MODE_IT_FALLING
PC13.GPIO_PuPd=GPIO_PULLUP
PC13.Signal=GPXTI13
PC6.GPIO_Label=M1_PWM_UH
PC6.GPIO_PuPd=GPIO_PULLDOWN
PC6.GPIO_Speed=GPIO_SPEED_FREQ_HIGH
PC6.Signal=S_TIM8_CH1
PC7.GPIO_Label=M1_PWM_VH
PC7.GPIO_PuPd=GPIO_PULLDOWN
PC7.GPIO_Speed=GPIO_SPEED_FREQ_HIGH
PC7.Signal=S_TIM8_CH2
PC8.GPIO_Label=M1_PWM_WH
PC8.GPIO_PuPd=GPIO_PULLDOWN
PC8.GPIO_Speed=GPIO_SPEED_FREQ_HIGH
PC8.Signal=S_TIM8_CH3
PD10.GPIO_Label=M1_VOLT_U
PD10.Mode=IN7-Single-Ended
PD10.Signal=ADC3_IN7
PD11.GPIO_Label=M1_CURR_U
PD11.Mode=IN8-Single-Ended
PD11.Signal=ADC3_IN8
PD12.GPIO_Label=M1_CURR_V
PD12.Mode=IN9-Single-Ended
PD12.Signal=ADC4_IN9
PD13.GPIO_Label=M1_VOLT_W
PD13.Mode=IN10-Single-Ended
PD13.Signal=ADC5_IN10
PD14.GPIO_Label=M1_CURR_W
PD14.Mode=IN11-Single-Ended
PD14.Signal=ADC5_IN11
PE12.GPIO_Label=M1_VOLT_V
PE12.Mode=IN16-Single-Ended
PE12.Signal=ADC4_IN16
PE15.GPIO_Label=M1_TEMPERATURE
PE15.Mode=IN2-Single-Ended
PE15.Signal=ADC4_IN2
PG6.GPIO_Label=DS18B20_DQ
PG6.GPIO_ModeDefaultOutputPP=GPIO_MODE_OUTPUT_OD
PG6.GPIO_PuPd=GPIO_NOPULL
PG6.PinState=GPIO_PIN_SET
PG6.Signal=GPIO_Output
PG7.GPIO_Label=M1_EN_DRIVER
PG7.GPIO_PuPd=GPIO_PULLUP
PG7.PinState=GPIO_PIN_SET
PG7.Signal=GPIO_Output
PG9.GPIO_Label=UART_TX
PG9.GPIO_Mode=GPIO_MODE_AF_PP
PG9.GPIO_PuPd=GPIO_NOPULL
PG9.GPIO_Speed=GPIO_SPEED_FREQ_LOW
PG9.Mode=Asynchronous
PG9.Signal=USART1_TX
ProjectManager.HeapSize=0x200
ProjectManager.StackSize=0x400
ProjectManager.TargetToolchain=STM32CubeIDE
RCC.ADC12CLockSelection=RCC_ADC12CLKSOURCE_PLL
RCC.ADC12Freq_Value=42500000
RCC.ADC345CLockSelection=RCC_ADC345CLKSOURCE_PLL
RCC.ADC345Freq_Value=42500000
RCC.AHBFreq_Value=170000000
RCC.APB1Freq_Value=170000000
RCC.APB1TimFreq_Value=170000000
RCC.APB2Freq_Value=170000000
RCC.APB2TimFreq_Value=170000000
RCC.CK48CLockSelection=RCC_USBCLKSOURCE_PLL
RCC.CortexFreq_Value=170000000
RCC.EXTERNAL_CLOCK_VALUE=12288000
RCC.HCLKFreq_Value=170000000
RCC.HSE_VALUE=8000000
RCC.HSI48_VALUE=48000000
RCC.HSI_VALUE=16000000
RCC.LSE_VALUE=32768
RCC.PLLM=RCC_PLLM_DIV4
RCC.PLLN=85
RCC.PLLP=RCC_PLLP_DIV8
RCC.PREFETCH_ENABLE=1
RCC.SYSCLKFreq_VALUE=170000000
RCC.SYSCLKSource=RCC_SYSCLKSOURCE_PLLCLK
RCC.USBFreq_Value=170000000
RCC.VCOOutputFreq_Value=340000000
SH.S_TIM8_CH1.0=TIM8_CH1,PWM Generation1 CH1 CH1N
SH.S_TIM8_CH2.0=TIM8_CH2,PWM Generation2 CH2 CH2N
SH.S_TIM8_CH3.0=TIM8_CH3,PWM Generation3 CH3 CH3N
SH.SharedAnalog_PB0.0=COMP4_INP,INP
SH.SharedAnalog_PB0.1=OPAMP3_VINP,Standalone
SH.SharedAnalog_PB11.0=COMP6_INP,INP
SH.SharedAnalog_PB11.1=OPAMP4_VINP,Standalone
SH.SharedAnalog_PB14.0=COMP7_INP,INP
SH.SharedAnalog_PB14.1=OPAMP5_VINP,Standalone
TIM3.AutoReloadPreload=TIM_AUTORELOAD_PRELOAD_DISABLE
TIM3.Channel-PWM\ Generation1\ No\ Output=TIM_CHANNEL_1
TIM3.ClockDivision=TIM_CLOCKDIVISION_DIV1
TIM3.CounterMode=TIM_COUNTERMODE_UP
TIM3.PeriodNoDither=M1_AUX_TIM_PERIOD_CYCLES
TIM3.Prescaler=((TIM_CLOCK_DIVIDER) - 1)
TIM3.PulseNoDither_1=(PWM_PERIOD_CYCLES/OVS_COUNT/2)+1
TIM3.TIM_MasterOutputTrigger=TIM_TRGO_OC1REF
TIM8.AutoReloadPreload=TIM_AUTORELOAD_PRELOAD_DISABLE
TIM8.AutomaticOutput=TIM_AUTOMATICOUTPUT_DISABLE
TIM8.Break2Filter=3
TIM8.Break2Polarity=TIM_BREAK2POLARITY_HIGH
TIM8.Break2State=TIM_BREAK2_DISABLE
TIM8.BreakFilter=4
TIM8.BreakPolarity=TIM_BREAKPOLARITY_HIGH
TIM8.BreakState=TIM_BREAK_ENABLE
TIM8.Channel=TIM_CHANNEL_4
TIM8.Channel-PWM\ Generation1\ CH1\ CH1N=TIM_CHANNEL_1
TIM8.Channel-PWM\ Generation2\ CH2\ CH2N=TIM_CHANNEL_2
TIM8.Channel-PWM\ Generation3\ CH3\ CH3N=TIM_CHANNEL_3
TIM8.Channel-PWM\ Generation4\ No\ Output=TIM_CHANNEL_4
TIM8.ClearInputSource=TIM_CLEARINPUTSOURCE_NONE
TIM8.ClockDivision=TIM_CLOCKDIVISION_DIV2
TIM8.CounterMode=TIM_COUNTERMODE_CENTERALIGNED2
TIM8.DeadTime=((DEAD_TIME_COUNTS) / 2)
TIM8.LockLevel=TIM_LOCKLEVEL_OFF
TIM8.OC1Preload_PWM=ENABLE
TIM8.OC2Preload_PWM=ENABLE
TIM8.OC3Preload_PWM=ENABLE
TIM8.OC4Preload_PWM=ENABLE
TIM8.OCFastMode_PWM=TIM_OCFAST_DISABLE
TIM8.OCIdleState_1=TIM_OCIDLESTATE_RESET
TIM8.OCIdleState_2=TIM_OCIDLESTATE_RESET
TIM8.OCIdleState_3=TIM_OCIDLESTATE_RESET
TIM8.OCIdleState_4=TIM_OCIDLESTATE_RESET
TIM8.OCMode_PWM-PWM\ Generation1\ CH1\ CH1N=TIM_OCMODE_PWM1
TIM8.OCMode_PWM-PWM\ Generation2\ CH2\ CH2N=TIM_OCMODE_PWM1
TIM8.OCMode_PWM-PWM\ Generation3\ CH3\ CH3N=TIM_OCMODE_PWM1
TIM8.OCMode_PWM-PWM\ Generation4\ No\ Output=TIM_OCMODE_PWM2
TIM8.OCNIdleState_1=TIM_OCNIDLESTATE_SET
TIM8.OCNIdleState_2=TIM_OCNIDLESTATE_SET
TIM8.OCNIdleState_3=TIM_OCNIDLESTATE_SET
TIM8.OCNPolarity_1=TIM_OCNPOLARITY_LOW
TIM8.OCNPolarity_2=TIM_OCNPOLARITY_LOW
TIM8.OCNPolarity_3=TIM_OCNPOLARITY_LOW
TIM8.OCPolarity_1=TIM_OCPOLARITY_HIGH
TIM8.OCPolarity_2=TIM_OCPOLARITY_HIGH
TIM8.OCPolarity_3=TIM_OCPOLARITY_HIGH
TIM8.OCPolarity_4=TIM_OCPOLARITY_HIGH
TIM8.OffStateIDLEMode=TIM_OSSI_ENABLE
TIM8.OffStateRunMode=TIM_OSSR_ENABLE
TIM8.PeriodNoDither=((PWM_PERIOD_CYCLES) / 2)
TIM8.Prescaler=((TIM_CLOCK_DIVIDER) - 1)
TIM8.PulseNoDither_1=((PWM_PERIOD_CYCLES) / 4)
TIM8.PulseNoDither_2=((PWM_PERIOD_CYCLES) / 4)
TIM8.PulseNoDither_3=((PWM_PERIOD_CYCLES) / 4)
TIM8.PulseNoDither_4=0
TIM8.RepetitionCounter=(REP_COUNTER)
TIM8.SourceBRK2DigInput=TIM_BREAKINPUTSOURCE_DISABLE
TIM8.SourceBRKCOMP4=TIM_BREAKINPUTSOURCE_ENABLE
TIM8.SourceBRKCOMP4Polarity=TIM_BREAKINPUTSOURCE_POLARITY_HIGH
TIM8.SourceBRKCOMP6=TIM_BREAKINPUTSOURCE_ENABLE
TIM8.SourceBRKCOMP6Polarity=TIM_BREAKINPUTSOURCE_POLARITY_HIGH
TIM8.SourceBRKCOMP7=TIM_BREAKINPUTSOURCE_ENABLE
TIM8.SourceBRKCOMP7Polarity=TIM_BREAKINPUTSOURCE_POLARITY_HIGH
TIM8.SourceBRKDigInput=TIM_BREAKINPUTSOURCE_ENABLE
TIM8.SourceBRKDigInputPolarity=TIM_BREAKINPUTSOURCE_POLARITY_LOW
TIM8.TIM_MasterOutputTrigger=TIM_TRGO_OC4REF
TIM8.TIM_MasterOutputTrigger2=TIM_TRGO2_RESET
TIM8.TIM_MasterSlaveMode=TIM_MASTERSLAVEMODE_DISABLE
TIM8.TIM_SlaveMode=TIM_SLAVEMODE_TRIGGER
USART1.BaudRate=1843200
USART1.VirtualMode-Asynchronous=VM_ASYNC
USART1.WordLength=WORDLENGTH_8B
VP_COMP4_VS_DAC3OUT2.Mode=INM_DAC3OUT2
VP_COMP6_VS_DAC4OUT2.Mode=INM_DAC4OUT2
VP_COMP7_VS_DAC4OUT1.Mode=INM_DAC4OUT1
VP_CORDIC_VS_CORDIC.Mode=CORDIC_Activate
VP_DAC3_VS_DACI2.Mode=DAC_OUT2_Int
VP_DAC4_VS_DACI1.Mode=DAC_OUT1_Int
VP_DAC4_VS_DACI2.Mode=DAC_OUT2_Int
VP_MotorControl_MC_ENABLED.Mode=Enabled
VP_SYS_VS_DBSignals.Mode=DisableDeadBatterySignals
VP_TIM3_VS_no_output1.Mode=PWM Generation1 No Output
VP_TIM8_VS_no_output4.Mode=PWM Generation4 No Output
board=custom

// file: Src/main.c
/* USER CODE BEGIN Header */
/**
  ******************************************************************************
  * @file           : main.c
  * @brief          : Main program body
  ******************************************************************************
  * @attention
  *
  * Copyright (c) 2026 STMicroelectronics.
  * All rights reserved.
  *
  * This software is licensed under terms that can be found in the LICENSE file
  * in the root directory of this software component.
  * If no LICENSE file comes with this software, it is provided AS-IS.
  *
  ******************************************************************************
  */
/* USER CODE END Header */
#include "main.h"

/* USER CODE BEGIN Includes */
#include "app_motor_control.h"
#include "app_datalog.h"
#include "app_foc_timing.h"
/* USER CODE END Includes */

ADC_HandleTypeDef hadc3;
ADC_HandleTypeDef hadc4;
ADC_HandleTypeDef hadc5;
DMA_HandleTypeDef hdma_adc3;
DMA_HandleTypeDef hdma_adc4;
DMA_HandleTypeDef hdma_adc5;

COMP_HandleTypeDef hcomp4;
COMP_HandleTypeDef hcomp6;
COMP_HandleTypeDef hcomp7;

CORDIC_HandleTypeDef hcordic;

DAC_HandleTypeDef hdac1;
DAC_HandleTypeDef hdac3;
DAC_HandleTypeDef hdac4;

OPAMP_HandleTypeDef hopamp3;
OPAMP_HandleTypeDef hopamp4;
OPAMP_HandleTypeDef hopamp5;

TIM_HandleTypeDef htim3;
TIM_HandleTypeDef htim8;

UART_HandleTypeDef huart1;
DMA_HandleTypeDef hdma_usart1_rx;
DMA_HandleTypeDef hdma_usart1_tx;

void SystemClock_Config(void);
static void MX_GPIO_Init(void);
static void MX_DMA_Init(void);
static void MX_ADC3_Init(void);
static void MX_ADC4_Init(void);
static void MX_ADC5_Init(void);
static void MX_COMP4_Init(void);
static void MX_COMP6_Init(void);
static void MX_COMP7_Init(void);
static void MX_CORDIC_Init(void);
static void MX_DAC1_Init(void);
static void MX_DAC3_Init(void);
static void MX_DAC4_Init(void);
static void MX_OPAMP3_Init(void);
static void MX_OPAMP4_Init(void);
static void MX_OPAMP5_Init(void);
static void MX_TIM3_Init(void);
static void MX_TIM8_Init(void);
static void MX_USART1_UART_Init(void);
static void MX_NVIC_Init(void);

int main(void)
{

  /* MCU Configuration--------------------------------------------------------*/

  /* Reset of all peripherals, Initializes the Flash interface and the Systick. */
  HAL_Init();

  /* Configure the system clock */
  SystemClock_Config();

  /* Initialize all configured peripherals */
  MX_GPIO_Init();
  MX_DMA_Init();
  MX_ADC3_Init();
  MX_ADC4_Init();
  MX_ADC5_Init();
  MX_COMP4_Init();
  MX_COMP6_Init();
  MX_COMP7_Init();
  MX_CORDIC_Init();
  MX_DAC1_Init();
  MX_DAC3_Init();
  MX_DAC4_Init();
  MX_OPAMP3_Init();
  MX_OPAMP4_Init();
  MX_OPAMP5_Init();
  MX_TIM3_Init();
  MX_TIM8_Init();
  MX_USART1_UART_Init();
  MX_MotorControl_Init();

  /* Initialize interrupts */
  MX_NVIC_Init();
  /* USER CODE BEGIN 2 */
  AppFocTiming_Init();
  AppDatalog_Init();
  AppMotorControl_Init();
  /* USER CODE END 2 */

  /* Infinite loop */
  while (1)
  {

    /* USER CODE BEGIN 3 */
	  AppMotorControl_Task();
	  AppDatalog_Task();
  }
  /* USER CODE END 3 */
}

void SystemClock_Config(void)
{
  RCC_OscInitTypeDef RCC_OscInitStruct = {0};
  RCC_ClkInitTypeDef RCC_ClkInitStruct = {0};

  /** Configure the main internal regulator output voltage
  */
  HAL_PWREx_ControlVoltageScaling(PWR_REGULATOR_VOLTAGE_SCALE1_BOOST);

  /** Initializes the RCC Oscillators according to the specified parameters
  * in the RCC_OscInitTypeDef structure.
  */
  RCC_OscInitStruct.OscillatorType = RCC_OSCILLATORTYPE_HSI;
  RCC_OscInitStruct.HSIState = RCC_HSI_ON;
  RCC_OscInitStruct.HSICalibrationValue = RCC_HSICALIBRATION_DEFAULT;
  RCC_OscInitStruct.PLL.PLLState = RCC_PLL_ON;
  RCC_OscInitStruct.PLL.PLLSource = RCC_PLLSOURCE_HSI;
  RCC_OscInitStruct.PLL.PLLM = RCC_PLLM_DIV4;
  RCC_OscInitStruct.PLL.PLLN = 85;
  RCC_OscInitStruct.PLL.PLLP = RCC_PLLP_DIV8;
  RCC_OscInitStruct.PLL.PLLQ = RCC_PLLQ_DIV2;
  RCC_OscInitStruct.PLL.PLLR = RCC_PLLR_DIV2;
  if (HAL_RCC_OscConfig(&RCC_OscInitStruct) != HAL_OK)
  {
    Error_Handler();
  }

  /** Initializes the CPU, AHB and APB buses clocks
  */
  RCC_ClkInitStruct.ClockType = RCC_CLOCKTYPE_HCLK|RCC_CLOCKTYPE_SYSCLK
                              |RCC_CLOCKTYPE_PCLK1|RCC_CLOCKTYPE_PCLK2;
  RCC_ClkInitStruct.SYSCLKSource = RCC_SYSCLKSOURCE_PLLCLK;
  RCC_ClkInitStruct.AHBCLKDivider = RCC_SYSCLK_DIV1;
  RCC_ClkInitStruct.APB1CLKDivider = RCC_HCLK_DIV1;
  RCC_ClkInitStruct.APB2CLKDivider = RCC_HCLK_DIV1;

  if (HAL_RCC_ClockConfig(&RCC_ClkInitStruct, FLASH_LATENCY_4) != HAL_OK)
  {
    Error_Handler();
  }
}

/**
  * @brief NVIC Configuration.
  * @retval None
  */
static void MX_NVIC_Init(void)
{
  /* USART1_IRQn interrupt configuration */
  HAL_NVIC_SetPriority(USART1_IRQn, 3, 1);
  HAL_NVIC_EnableIRQ(USART1_IRQn);
  /* DMA2_Channel3_IRQn interrupt configuration */
  HAL_NVIC_SetPriority(DMA2_Channel3_IRQn, 1, 0);
  HAL_NVIC_EnableIRQ(DMA2_Channel3_IRQn);
  /* DMA2_Channel2_IRQn interrupt configuration */
  HAL_NVIC_SetPriority(DMA2_Channel2_IRQn, 1, 0);
  HAL_NVIC_EnableIRQ(DMA2_Channel2_IRQn);
  /* DMA2_Channel1_IRQn interrupt configuration */
  HAL_NVIC_SetPriority(DMA2_Channel1_IRQn, 1, 0);
  HAL_NVIC_EnableIRQ(DMA2_Channel1_IRQn);
  /* DMA1_Channel1_IRQn interrupt configuration */
  HAL_NVIC_SetPriority(DMA1_Channel1_IRQn, 3, 0);
  HAL_NVIC_EnableIRQ(DMA1_Channel1_IRQn);
  /* TIM8_BRK_IRQn interrupt configuration */
  HAL_NVIC_SetPriority(TIM8_BRK_IRQn, 4, 1);
  HAL_NVIC_EnableIRQ(TIM8_BRK_IRQn);
  /* TIM8_UP_IRQn interrupt configuration */
  HAL_NVIC_SetPriority(TIM8_UP_IRQn, 0, 0);
  HAL_NVIC_EnableIRQ(TIM8_UP_IRQn);
  /* TIM8_CC_IRQn interrupt configuration */
  HAL_NVIC_SetPriority(TIM8_CC_IRQn, 0, 0);
  HAL_NVIC_EnableIRQ(TIM8_CC_IRQn);
  /* EXTI15_10_IRQn interrupt configuration */
  HAL_NVIC_SetPriority(EXTI15_10_IRQn, 3, 0);
  HAL_NVIC_EnableIRQ(EXTI15_10_IRQn);
}

static void MX_ADC3_Init(void)
{

  ADC_MultiModeTypeDef multimode = {0};
  ADC_ChannelConfTypeDef sConfig = {0};

  /** Common config
  */
  hadc3.Instance = ADC3;
  hadc3.Init.ClockPrescaler = ADC_CLOCK_ASYNC_DIV1;
  hadc3.Init.Resolution = ADC_RESOLUTION_12B;
  hadc3.Init.DataAlign = ADC_DATAALIGN_LEFT;
  hadc3.Init.GainCompensation = 0;
  hadc3.Init.ScanConvMode = ADC_SCAN_ENABLE;
  hadc3.Init.EOCSelection = ADC_EOC_SINGLE_CONV;
  hadc3.Init.LowPowerAutoWait = DISABLE;
  hadc3.Init.ContinuousConvMode = DISABLE;
  hadc3.Init.NbrOfConversion = 3;
  hadc3.Init.DiscontinuousConvMode = DISABLE;
  hadc3.Init.ExternalTrigConv = ADC_EXTERNALTRIG_T3_TRGO;
  hadc3.Init.ExternalTrigConvEdge = ADC_EXTERNALTRIGCONVEDGE_FALLING;
  hadc3.Init.DMAContinuousRequests = DISABLE;
  hadc3.Init.Overrun = ADC_OVR_DATA_PRESERVED;
  hadc3.Init.OversamplingMode = DISABLE;
  if (HAL_ADC_Init(&hadc3) != HAL_OK)
  {
    Error_Handler();
  }

  /** Configure the ADC multi-mode
  */
  multimode.Mode = ADC_MODE_INDEPENDENT;
  if (HAL_ADCEx_MultiModeConfigChannel(&hadc3, &multimode) != HAL_OK)
  {
    Error_Handler();
  }

  /** Configure Regular Channel
  */
  sConfig.Channel = ADC_CHANNEL_8;
  sConfig.Rank = ADC_REGULAR_RANK_1;
  sConfig.SamplingTime = ADC_SAMPLETIME_6CYCLES_5;
  sConfig.SingleDiff = ADC_SINGLE_ENDED;
  sConfig.OffsetNumber = ADC_OFFSET_NONE;
  sConfig.Offset = 0;
  if (HAL_ADC_ConfigChannel(&hadc3, &sConfig) != HAL_OK)
  {
    Error_Handler();
  }

  /** Configure Regular Channel
  */
  sConfig.Channel = ADC_CHANNEL_7;
  sConfig.Rank = ADC_REGULAR_RANK_2;
  if (HAL_ADC_ConfigChannel(&hadc3, &sConfig) != HAL_OK)
  {
    Error_Handler();
  }

  /** Configure Regular Channel
  */
  sConfig.Channel = ADC_CHANNEL_5;
  sConfig.Rank = ADC_REGULAR_RANK_3;
  if (HAL_ADC_ConfigChannel(&hadc3, &sConfig) != HAL_OK)
  {
    Error_Handler();
  }

}

static void MX_ADC4_Init(void)
{

  ADC_ChannelConfTypeDef sConfig = {0};

  /** Common config
  */
  hadc4.Instance = ADC4;
  hadc4.Init.ClockPrescaler = ADC_CLOCK_ASYNC_DIV1;
  hadc4.Init.Resolution = ADC_RESOLUTION_12B;
  hadc4.Init.DataAlign = ADC_DATAALIGN_LEFT;
  hadc4.Init.GainCompensation = 0;
  hadc4.Init.ScanConvMode = ADC_SCAN_ENABLE;
  hadc4.Init.EOCSelection = ADC_EOC_SINGLE_CONV;
  hadc4.Init.LowPowerAutoWait = DISABLE;
  hadc4.Init.ContinuousConvMode = DISABLE;
  hadc4.Init.NbrOfConversion = 3;
  hadc4.Init.DiscontinuousConvMode = DISABLE;
  hadc4.Init.ExternalTrigConv = ADC_EXTERNALTRIG_T3_TRGO;
  hadc4.Init.ExternalTrigConvEdge = ADC_EXTERNALTRIGCONVEDGE_FALLING;
  hadc4.Init.DMAContinuousRequests = DISABLE;
  hadc4.Init.Overrun = ADC_OVR_DATA_PRESERVED;
  hadc4.Init.OversamplingMode = DISABLE;
  if (HAL_ADC_Init(&hadc4) != HAL_OK)
  {
    Error_Handler();
  }

  /** Configure Regular Channel
  */
  sConfig.Channel = ADC_CHANNEL_9;
  sConfig.Rank = ADC_REGULAR_RANK_1;
  sConfig.SamplingTime = ADC_SAMPLETIME_6CYCLES_5;
  sConfig.SingleDiff = ADC_SINGLE_ENDED;
  sConfig.OffsetNumber = ADC_OFFSET_NONE;
  sConfig.Offset = 0;
  if (HAL_ADC_ConfigChannel(&hadc4, &sConfig) != HAL_OK)
  {
    Error_Handler();
  }

  /** Configure Regular Channel
  */
  sConfig.Channel = ADC_CHANNEL_16;
  sConfig.Rank = ADC_REGULAR_RANK_2;
  if (HAL_ADC_ConfigChannel(&hadc4, &sConfig) != HAL_OK)
  {
    Error_Handler();
  }

  /** Configure Regular Channel
  */
  sConfig.Channel = ADC_CHANNEL_2;
  sConfig.Rank = ADC_REGULAR_RANK_3;
  if (HAL_ADC_ConfigChannel(&hadc4, &sConfig) != HAL_OK)
  {
    Error_Handler();
  }

}

static void MX_ADC5_Init(void)
{

  ADC_ChannelConfTypeDef sConfig = {0};

  /** Common config
  */
  hadc5.Instance = ADC5;
  hadc5.Init.ClockPrescaler = ADC_CLOCK_ASYNC_DIV1;
  hadc5.Init.Resolution = ADC_RESOLUTION_12B;
  hadc5.Init.DataAlign = ADC_DATAALIGN_LEFT;
  hadc5.Init.GainCompensation = 0;
  hadc5.Init.ScanConvMode = ADC_SCAN_ENABLE;
  hadc5.Init.EOCSelection = ADC_EOC_SINGLE_CONV;
  hadc5.Init.LowPowerAutoWait = DISABLE;
  hadc5.Init.ContinuousConvMode = DISABLE;
  hadc5.Init.NbrOfConversion = 3;
  hadc5.Init.DiscontinuousConvMode = DISABLE;
  hadc5.Init.ExternalTrigConv = ADC_EXTERNALTRIG_T3_TRGO;
  hadc5.Init.ExternalTrigConvEdge = ADC_EXTERNALTRIGCONVEDGE_FALLING;
  hadc5.Init.DMAContinuousRequests = DISABLE;
  hadc5.Init.Overrun = ADC_OVR_DATA_PRESERVED;
  hadc5.Init.OversamplingMode = DISABLE;
  if (HAL_ADC_Init(&hadc5) != HAL_OK)
  {
    Error_Handler();
  }

  /** Configure Regular Channel
  */
  sConfig.Channel = ADC_CHANNEL_11;
  sConfig.Rank = ADC_REGULAR_RANK_1;
  sConfig.SamplingTime = ADC_SAMPLETIME_6CYCLES_5;
  sConfig.SingleDiff = ADC_SINGLE_ENDED;
  sConfig.OffsetNumber = ADC_OFFSET_NONE;
  sConfig.Offset = 0;
  if (HAL_ADC_ConfigChannel(&hadc5, &sConfig) != HAL_OK)
  {
    Error_Handler();
  }

  /** Configure Regular Channel
  */
  sConfig.Channel = ADC_CHANNEL_10;
  sConfig.Rank = ADC_REGULAR_RANK_2;
  if (HAL_ADC_ConfigChannel(&hadc5, &sConfig) != HAL_OK)
  {
    Error_Handler();
  }

  /** Configure Regular Channel
  */
  sConfig.Rank = ADC_REGULAR_RANK_3;
  if (HAL_ADC_ConfigChannel(&hadc5, &sConfig) != HAL_OK)
  {
    Error_Handler();
  }

}

static void MX_COMP4_Init(void)
{

  hcomp4.Instance = COMP4;
  hcomp4.Init.InputPlus = COMP_INPUT_PLUS_IO1;
  hcomp4.Init.InputMinus = COMP_INPUT_MINUS_DAC3_CH2;
  hcomp4.Init.OutputPol = COMP_OUTPUTPOL_NONINVERTED;
  hcomp4.Init.Hysteresis = COMP_HYSTERESIS_NONE;
  hcomp4.Init.BlankingSrce = COMP_BLANKINGSRC_NONE;
  hcomp4.Init.TriggerMode = COMP_TRIGGERMODE_NONE;
  if (HAL_COMP_Init(&hcomp4) != HAL_OK)
  {
    Error_Handler();
  }

}

static void MX_COMP6_Init(void)
{

  hcomp6.Instance = COMP6;
  hcomp6.Init.InputPlus = COMP_INPUT_PLUS_IO1;
  hcomp6.Init.InputMinus = COMP_INPUT_MINUS_DAC4_CH2;
  hcomp6.Init.OutputPol = COMP_OUTPUTPOL_NONINVERTED;
  hcomp6.Init.Hysteresis = COMP_HYSTERESIS_NONE;
  hcomp6.Init.BlankingSrce = COMP_BLANKINGSRC_NONE;
  hcomp6.Init.TriggerMode = COMP_TRIGGERMODE_NONE;
  if (HAL_COMP_Init(&hcomp6) != HAL_OK)
  {
    Error_Handler();
  }

}

static void MX_COMP7_Init(void)
{

  hcomp7.Instance = COMP7;
  hcomp7.Init.InputPlus = COMP_INPUT_PLUS_IO1;
  hcomp7.Init.InputMinus = COMP_INPUT_MINUS_DAC4_CH1;
  hcomp7.Init.OutputPol = COMP_OUTPUTPOL_NONINVERTED;
  hcomp7.Init.Hysteresis = COMP_HYSTERESIS_NONE;
  hcomp7.Init.BlankingSrce = COMP_BLANKINGSRC_NONE;
  hcomp7.Init.TriggerMode = COMP_TRIGGERMODE_NONE;
  if (HAL_COMP_Init(&hcomp7) != HAL_OK)
  {
    Error_Handler();
  }

}

static void MX_CORDIC_Init(void)
{

  hcordic.Instance = CORDIC;
  if (HAL_CORDIC_Init(&hcordic) != HAL_OK)
  {
    Error_Handler();
  }

}

static void MX_DAC1_Init(void)
{

  DAC_ChannelConfTypeDef sConfig = {0};

  /** DAC1 channel 2 drives the TB-200S ADJ input through a 1 kohm resistor.
  */
  hdac1.Instance = DAC1;
  if (HAL_DAC_Init(&hdac1) != HAL_OK)
  {
    Error_Handler();
  }

  sConfig.DAC_HighFrequency = DAC_HIGH_FREQUENCY_INTERFACE_MODE_AUTOMATIC;
  sConfig.DAC_DMADoubleDataMode = DISABLE;
  sConfig.DAC_SignedFormat = DISABLE;
  sConfig.DAC_SampleAndHold = DAC_SAMPLEANDHOLD_DISABLE;
  sConfig.DAC_Trigger = DAC_TRIGGER_NONE;
  sConfig.DAC_Trigger2 = DAC_TRIGGER_NONE;
  sConfig.DAC_OutputBuffer = DAC_OUTPUTBUFFER_ENABLE;
  sConfig.DAC_ConnectOnChipPeripheral = DAC_CHIPCONNECT_EXTERNAL;
  sConfig.DAC_UserTrimming = DAC_TRIMMING_FACTORY;
  if (HAL_DAC_ConfigChannel(&hdac1, &sConfig, DAC_CHANNEL_2) != HAL_OK)
  {
    Error_Handler();
  }
}

static void MX_DAC3_Init(void)
{

  DAC_ChannelConfTypeDef sConfig = {0};

  /** DAC Initialization
  */
  hdac3.Instance = DAC3;
  if (HAL_DAC_Init(&hdac3) != HAL_OK)
  {
    Error_Handler();
  }

  /** DAC channel OUT2 config
  */
  sConfig.DAC_HighFrequency = DAC_HIGH_FREQUENCY_INTERFACE_MODE_AUTOMATIC;
  sConfig.DAC_DMADoubleDataMode = DISABLE;
  sConfig.DAC_SignedFormat = DISABLE;
  sConfig.DAC_SampleAndHold = DAC_SAMPLEANDHOLD_DISABLE;
  sConfig.DAC_Trigger = DAC_TRIGGER_NONE;
  sConfig.DAC_Trigger2 = DAC_TRIGGER_NONE;
  sConfig.DAC_OutputBuffer = DAC_OUTPUTBUFFER_DISABLE;
  sConfig.DAC_ConnectOnChipPeripheral = DAC_CHIPCONNECT_INTERNAL;
  sConfig.DAC_UserTrimming = DAC_TRIMMING_FACTORY;
  if (HAL_DAC_ConfigChannel(&hdac3, &sConfig, DAC_CHANNEL_2) != HAL_OK)
  {
    Error_Handler();
  }

}

static void MX_DAC4_Init(void)
{

  DAC_ChannelConfTypeDef sConfig = {0};

  /** DAC Initialization
  */
  hdac4.Instance = DAC4;
  if (HAL_DAC_Init(&hdac4) != HAL_OK)
  {
    Error_Handler();
  }

  /** DAC channel OUT1 config
  */
  sConfig.DAC_HighFrequency = DAC_HIGH_FREQUENCY_INTERFACE_MODE_AUTOMATIC;
  sConfig.DAC_DMADoubleDataMode = DISABLE;
  sConfig.DAC_SignedFormat = DISABLE;
  sConfig.DAC_SampleAndHold = DAC_SAMPLEANDHOLD_DISABLE;
  sConfig.DAC_Trigger = DAC_TRIGGER_NONE;
  sConfig.DAC_Trigger2 = DAC_TRIGGER_NONE;
  sConfig.DAC_OutputBuffer = DAC_OUTPUTBUFFER_DISABLE;
  sConfig.DAC_ConnectOnChipPeripheral = DAC_CHIPCONNECT_INTERNAL;
  sConfig.DAC_UserTrimming = DAC_TRIMMING_FACTORY;
  if (HAL_DAC_ConfigChannel(&hdac4, &sConfig, DAC_CHANNEL_1) != HAL_OK)
  {
    Error_Handler();
  }

  /** DAC channel OUT2 config
  */
  if (HAL_DAC_ConfigChannel(&hdac4, &sConfig, DAC_CHANNEL_2) != HAL_OK)
  {
    Error_Handler();
  }

}

static void MX_OPAMP3_Init(void)
{

  hopamp3.Instance = OPAMP3;
  hopamp3.Init.PowerMode = OPAMP_POWERMODE_NORMALSPEED;
  hopamp3.Init.Mode = OPAMP_STANDALONE_MODE;
  hopamp3.Init.InvertingInput = OPAMP_INVERTINGINPUT_IO0;
  hopamp3.Init.NonInvertingInput = OPAMP_NONINVERTINGINPUT_IO0;
  hopamp3.Init.InternalOutput = DISABLE;
  hopamp3.Init.TimerControlledMuxmode = OPAMP_TIMERCONTROLLEDMUXMODE_DISABLE;
  hopamp3.Init.UserTrimming = OPAMP_TRIMMING_FACTORY;
  if (HAL_OPAMP_Init(&hopamp3) != HAL_OK)
  {
    Error_Handler();
  }

}

static void MX_OPAMP4_Init(void)
{

  hopamp4.Instance = OPAMP4;
  hopamp4.Init.PowerMode = OPAMP_POWERMODE_NORMALSPEED;
  hopamp4.Init.Mode = OPAMP_STANDALONE_MODE;
  hopamp4.Init.InvertingInput = OPAMP_INVERTINGINPUT_IO0;
  hopamp4.Init.NonInvertingInput = OPAMP_NONINVERTINGINPUT_IO2;
  hopamp4.Init.InternalOutput = DISABLE;
  hopamp4.Init.TimerControlledMuxmode = OPAMP_TIMERCONTROLLEDMUXMODE_DISABLE;
  hopamp4.Init.UserTrimming = OPAMP_TRIMMING_FACTORY;
  if (HAL_OPAMP_Init(&hopamp4) != HAL_OK)
  {
    Error_Handler();
  }

}

static void MX_OPAMP5_Init(void)
{

  hopamp5.Instance = OPAMP5;
  hopamp5.Init.PowerMode = OPAMP_POWERMODE_NORMALSPEED;
  hopamp5.Init.Mode = OPAMP_STANDALONE_MODE;
  hopamp5.Init.InvertingInput = OPAMP_INVERTINGINPUT_IO0;
  hopamp5.Init.NonInvertingInput = OPAMP_NONINVERTINGINPUT_IO0;
  hopamp5.Init.InternalOutput = DISABLE;
  hopamp5.Init.TimerControlledMuxmode = OPAMP_TIMERCONTROLLEDMUXMODE_DISABLE;
  hopamp5.Init.UserTrimming = OPAMP_TRIMMING_FACTORY;
  if (HAL_OPAMP_Init(&hopamp5) != HAL_OK)
  {
    Error_Handler();
  }

}

static void MX_TIM3_Init(void)
{

  TIM_MasterConfigTypeDef sMasterConfig = {0};
  TIM_OC_InitTypeDef sConfigOC = {0};

  htim3.Instance = TIM3;
  htim3.Init.Prescaler = ((TIM_CLOCK_DIVIDER) - 1);
  htim3.Init.CounterMode = TIM_COUNTERMODE_UP;
  htim3.Init.Period = M1_AUX_TIM_PERIOD_CYCLES;
  htim3.Init.ClockDivision = TIM_CLOCKDIVISION_DIV1;
  htim3.Init.AutoReloadPreload = TIM_AUTORELOAD_PRELOAD_DISABLE;
  if (HAL_TIM_PWM_Init(&htim3) != HAL_OK)
  {
    Error_Handler();
  }
  sMasterConfig.MasterOutputTrigger = TIM_TRGO_OC1REF;
  sMasterConfig.MasterSlaveMode = TIM_MASTERSLAVEMODE_DISABLE;
  if (HAL_TIMEx_MasterConfigSynchronization(&htim3, &sMasterConfig) != HAL_OK)
  {
    Error_Handler();
  }
  sConfigOC.OCMode = TIM_OCMODE_PWM1;
  sConfigOC.Pulse = (PWM_PERIOD_CYCLES/OVS_COUNT/2)+1;
  sConfigOC.OCPolarity = TIM_OCPOLARITY_HIGH;
  sConfigOC.OCFastMode = TIM_OCFAST_DISABLE;
  if (HAL_TIM_PWM_ConfigChannel(&htim3, &sConfigOC, TIM_CHANNEL_1) != HAL_OK)
  {
    Error_Handler();
  }

}

static void MX_TIM8_Init(void)
{

  TIM_MasterConfigTypeDef sMasterConfig = {0};
  TIMEx_BreakInputConfigTypeDef sBreakInputConfig = {0};
  TIM_OC_InitTypeDef sConfigOC = {0};
  TIM_BreakDeadTimeConfigTypeDef sBreakDeadTimeConfig = {0};

  htim8.Instance = TIM8;
  htim8.Init.Prescaler = ((TIM_CLOCK_DIVIDER) - 1);
  htim8.Init.CounterMode = TIM_COUNTERMODE_CENTERALIGNED2;
  htim8.Init.Period = ((PWM_PERIOD_CYCLES) / 2);
  htim8.Init.ClockDivision = TIM_CLOCKDIVISION_DIV2;
  htim8.Init.RepetitionCounter = (REP_COUNTER);
  htim8.Init.AutoReloadPreload = TIM_AUTORELOAD_PRELOAD_DISABLE;
  if (HAL_TIM_PWM_Init(&htim8) != HAL_OK)
  {
    Error_Handler();
  }
  sMasterConfig.MasterOutputTrigger = TIM_TRGO_OC4REF;
  sMasterConfig.MasterOutputTrigger2 = TIM_TRGO2_RESET;
  sMasterConfig.MasterSlaveMode = TIM_MASTERSLAVEMODE_DISABLE;
  if (HAL_TIMEx_MasterConfigSynchronization(&htim8, &sMasterConfig) != HAL_OK)
  {
    Error_Handler();
  }
  sBreakInputConfig.Source = TIM_BREAKINPUTSOURCE_BKIN;
  sBreakInputConfig.Enable = TIM_BREAKINPUTSOURCE_ENABLE;
  sBreakInputConfig.Polarity = TIM_BREAKINPUTSOURCE_POLARITY_LOW;
  if (HAL_TIMEx_ConfigBreakInput(&htim8, TIM_BREAKINPUT_BRK, &sBreakInputConfig) != HAL_OK)
  {
    Error_Handler();
  }
  sBreakInputConfig.Source = TIM_BREAKINPUTSOURCE_COMP4;
  sBreakInputConfig.Polarity = TIM_BREAKINPUTSOURCE_POLARITY_HIGH;
  if (HAL_TIMEx_ConfigBreakInput(&htim8, TIM_BREAKINPUT_BRK, &sBreakInputConfig) != HAL_OK)
  {
    Error_Handler();
  }
  sBreakInputConfig.Source = TIM_BREAKINPUTSOURCE_COMP6;

  if (HAL_TIMEx_ConfigBreakInput(&htim8, TIM_BREAKINPUT_BRK, &sBreakInputConfig) != HAL_OK)
  {
    Error_Handler();
  }
  sBreakInputConfig.Source = TIM_BREAKINPUTSOURCE_COMP7;

  if (HAL_TIMEx_ConfigBreakInput(&htim8, TIM_BREAKINPUT_BRK, &sBreakInputConfig) != HAL_OK)
  {
    Error_Handler();
  }
  sConfigOC.OCMode = TIM_OCMODE_PWM1;
  sConfigOC.Pulse = ((PWM_PERIOD_CYCLES) / 4);
  sConfigOC.OCPolarity = TIM_OCPOLARITY_HIGH;
  sConfigOC.OCNPolarity = TIM_OCNPOLARITY_LOW;
  sConfigOC.OCFastMode = TIM_OCFAST_DISABLE;
  sConfigOC.OCIdleState = TIM_OCIDLESTATE_RESET;
  sConfigOC.OCNIdleState = TIM_OCNIDLESTATE_SET;
  if (HAL_TIM_PWM_ConfigChannel(&htim8, &sConfigOC, TIM_CHANNEL_1) != HAL_OK)
  {
    Error_Handler();
  }
  if (HAL_TIM_PWM_ConfigChannel(&htim8, &sConfigOC, TIM_CHANNEL_2) != HAL_OK)
  {
    Error_Handler();
  }
  if (HAL_TIM_PWM_ConfigChannel(&htim8, &sConfigOC, TIM_CHANNEL_3) != HAL_OK)
  {
    Error_Handler();
  }
  sConfigOC.OCMode = TIM_OCMODE_PWM2;
  sConfigOC.Pulse = 0;
  sConfigOC.OCNPolarity = TIM_OCNPOLARITY_HIGH;
  sConfigOC.OCNIdleState = TIM_OCNIDLESTATE_RESET;
  if (HAL_TIM_PWM_ConfigChannel(&htim8, &sConfigOC, TIM_CHANNEL_4) != HAL_OK)
  {
    Error_Handler();
  }
  sBreakDeadTimeConfig.OffStateRunMode = TIM_OSSR_ENABLE;
  sBreakDeadTimeConfig.OffStateIDLEMode = TIM_OSSI_ENABLE;
  sBreakDeadTimeConfig.LockLevel = TIM_LOCKLEVEL_OFF;
  sBreakDeadTimeConfig.DeadTime = ((DEAD_TIME_COUNTS) / 2);
  sBreakDeadTimeConfig.BreakState = TIM_BREAK_ENABLE;
  sBreakDeadTimeConfig.BreakPolarity = TIM_BREAKPOLARITY_HIGH;
  sBreakDeadTimeConfig.BreakFilter = 4;
  sBreakDeadTimeConfig.BreakAFMode = TIM_BREAK_AFMODE_INPUT;
  sBreakDeadTimeConfig.Break2State = TIM_BREAK2_DISABLE;
  sBreakDeadTimeConfig.Break2Polarity = TIM_BREAK2POLARITY_HIGH;
  sBreakDeadTimeConfig.Break2Filter = 3;
  sBreakDeadTimeConfig.Break2AFMode = TIM_BREAK_AFMODE_INPUT;
  sBreakDeadTimeConfig.AutomaticOutput = TIM_AUTOMATICOUTPUT_DISABLE;
  if (HAL_TIMEx_ConfigBreakDeadTime(&htim8, &sBreakDeadTimeConfig) != HAL_OK)
  {
    Error_Handler();
  }
  HAL_TIM_MspPostInit(&htim8);

}

static void MX_USART1_UART_Init(void)
{

  huart1.Instance = USART1;
  huart1.Init.BaudRate = 115200;
  huart1.Init.WordLength = UART_WORDLENGTH_8B;
  huart1.Init.StopBits = UART_STOPBITS_1;
  huart1.Init.Parity = UART_PARITY_NONE;
  huart1.Init.Mode = UART_MODE_TX_RX;
  huart1.Init.HwFlowCtl = UART_HWCONTROL_NONE;
  huart1.Init.OverSampling = UART_OVERSAMPLING_16;
  huart1.Init.OneBitSampling = UART_ONE_BIT_SAMPLE_DISABLE;
  huart1.Init.ClockPrescaler = UART_PRESCALER_DIV1;
  huart1.AdvancedInit.AdvFeatureInit = UART_ADVFEATURE_NO_INIT;
  if (HAL_UART_Init(&huart1) != HAL_OK)
  {
    Error_Handler();
  }
  if (HAL_UARTEx_SetTxFifoThreshold(&huart1, UART_TXFIFO_THRESHOLD_1_8) != HAL_OK)
  {
    Error_Handler();
  }
  if (HAL_UARTEx_SetRxFifoThreshold(&huart1, UART_RXFIFO_THRESHOLD_1_8) != HAL_OK)
  {
    Error_Handler();
  }
  if (HAL_UARTEx_DisableFifoMode(&huart1) != HAL_OK)
  {
    Error_Handler();
  }

}

static void MX_DMA_Init(void)
{

  /* DMA controller clock enable */
  __HAL_RCC_DMAMUX1_CLK_ENABLE();
  __HAL_RCC_DMA2_CLK_ENABLE();
  __HAL_RCC_DMA1_CLK_ENABLE();

}

static void MX_GPIO_Init(void)
{
  GPIO_InitTypeDef GPIO_InitStruct = {0};

  /* GPIO Ports Clock Enable */
  __HAL_RCC_GPIOC_CLK_ENABLE();
  __HAL_RCC_GPIOB_CLK_ENABLE();
  __HAL_RCC_GPIOE_CLK_ENABLE();
  __HAL_RCC_GPIOD_CLK_ENABLE();
  __HAL_RCC_GPIOA_CLK_ENABLE();
  __HAL_RCC_GPIOG_CLK_ENABLE();

  /*Configure GPIO pin Output Level */
  HAL_GPIO_WritePin(GPIOG, DS18B20_DQ_Pin|M1_EN_DRIVER_Pin, GPIO_PIN_SET);

  /*Configure GPIO pin : Start_Stop_Pin */
  GPIO_InitStruct.Pin = Start_Stop_Pin;
  GPIO_InitStruct.Mode = GPIO_MODE_IT_FALLING;
  GPIO_InitStruct.Pull = GPIO_PULLUP;
  HAL_GPIO_Init(Start_Stop_GPIO_Port, &GPIO_InitStruct);

  /*Configure GPIO pin : DS18B20_DQ_Pin */
  GPIO_InitStruct.Pin = DS18B20_DQ_Pin;
  GPIO_InitStruct.Mode = GPIO_MODE_OUTPUT_OD;
  GPIO_InitStruct.Pull = GPIO_NOPULL;
  GPIO_InitStruct.Speed = GPIO_SPEED_FREQ_LOW;
  HAL_GPIO_Init(DS18B20_DQ_GPIO_Port, &GPIO_InitStruct);

  /*Configure GPIO pin : M1_EN_DRIVER_Pin */
  GPIO_InitStruct.Pin = M1_EN_DRIVER_Pin;
  GPIO_InitStruct.Mode = GPIO_MODE_OUTPUT_PP;
  GPIO_InitStruct.Pull = GPIO_PULLUP;
  GPIO_InitStruct.Speed = GPIO_SPEED_FREQ_LOW;
  HAL_GPIO_Init(M1_EN_DRIVER_GPIO_Port, &GPIO_InitStruct);

}

void Error_Handler(void)
{
  __disable_irq();
  while (1)
  {
  }
}
